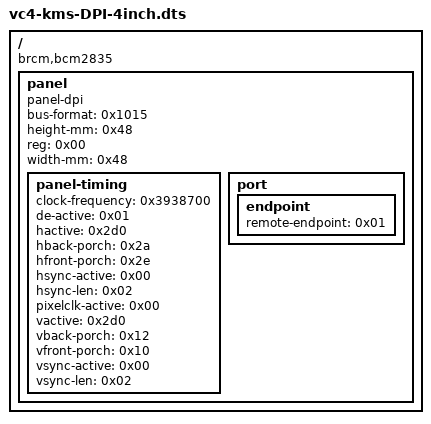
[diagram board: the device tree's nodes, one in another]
<stdout>: Warning (reg_format): /fragment@0/__overlay__/panel:reg: property has invalid length (4 bytes) (#address-cells == 2, #size-cells == 1)
<stdout>: Warning (unit_address_vs_reg): /fragment@0/__overlay__/panel: node has a reg or ranges property, but no unit name
<stdout>: Warning (pci_device_reg): Failed prerequisite 'reg_format'
<stdout>: Warning (pci_device_bus_num): Failed prerequisite 'reg_format'
<stdout>: Warning (simple_bus_reg): Failed prerequisite 'reg_format'
<stdout>: Warning (i2c_bus_reg): Failed prerequisite 'reg_format'
<stdout>: Warning (spi_bus_reg): Failed prerequisite 'reg_format'
<stdout>: Warning (avoid_default_addr_size): /fragment@0/__overlay__/panel: Relying on default #address-cells value
<stdout>: Warning (avoid_default_addr_size): /fragment@0/__overlay__/panel: Relying on default #size-cells value
<stdout>: Warning (avoid_unnecessary_addr_size): Failed prerequisite 'avoid_default_addr_size'
<stdout>: Warning (unique_unit_address): Failed prerequisite 'avoid_default_addr_size'
<stdout>: Warning (gpios_property): /fragment@2/__overlay__/wittypi_led:gpios: Could not get phandle node for (cell 1)
<stdout>: Warning (gpios_property): /__fixups__:gpio: Could not get phandle node for (cell 0)
/dts-v1/;

/ {
	compatible = "brcm,bcm2835";

	__fixups__ {
		dpi = "/fragment@1:target:0";
		dpi_18bit_cpadhi_gpio0 = "/fragment@1/__overlay__:pinctrl-0:0";
		gpio = "/fragment@2/__overlay__/wittypi_led:gpios:0";
		leds = "/fragment@2:target:0";
	};

	__local_fixups__ {

		fragment@0 {

			__overlay__ {

				panel {

					port {

						endpoint {
							remote-endpoint = <0x00>;
						};
					};
				};
			};
		};

		fragment@1 {

			__overlay__ {

				port {

					endpoint {
						remote-endpoint = <0x00>;
					};
				};
			};
		};
	};

	__symbols__ {
		dpi_node = "/fragment@1/__overlay__";
		dpi_out = "/fragment@1/__overlay__/port/endpoint";
		panel = "/fragment@0/__overlay__/panel";
		panel_in = "/fragment@0/__overlay__/panel/port/endpoint";
		timing = "/fragment@0/__overlay__/panel/panel-timing";
		wittypi_led = "/fragment@2/__overlay__/wittypi_led";
	};

	fragment@0 {
		target-path = "/";

		__overlay__ {

			panel {
				bus-format = <0x1015>;
				compatible = "panel-dpi";
				height-mm = <0x48>;
				phandle = <0x03>;
				reg = <0x00>;
				width-mm = <0x48>;

				panel-timing {
					clock-frequency = <0x3938700>;
					de-active = <0x01>;
					hactive = <0x2d0>;
					hback-porch = <0x2a>;
					hfront-porch = <0x2e>;
					hsync-active = <0x00>;
					hsync-len = <0x02>;
					phandle = <0x04>;
					pixelclk-active = <0x00>;
					vactive = <0x2d0>;
					vback-porch = <0x12>;
					vfront-porch = <0x10>;
					vsync-active = <0x00>;
					vsync-len = <0x02>;
				};

				port {

					endpoint {
						phandle = <0x02>;
						remote-endpoint = <0x01>;
					};
				};
			};
		};
	};

	fragment@1 {
		target = <0xffffffff>;

		__overlay__ {
			phandle = <0x05>;
			pinctrl-0 = <0xffffffff>;
			pinctrl-names = "default";
			status = "okay";

			port {

				endpoint {
					phandle = <0x01>;
					remote-endpoint = <0x02>;
				};
			};
		};
	};

	fragment@2 {
		target = <0xffffffff>;

		__overlay__ {
			compatible = "gpio-leds";

			wittypi_led {
				gpios = <0xffffffff 0x12 0x01>;
				label = "wittypi_led";
				linux,default-trigger = "default-on";
				phandle = <0x06>;
			};
		};
	};
};
